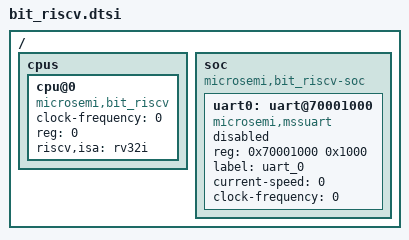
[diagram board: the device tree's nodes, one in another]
/*
 *
 * SPDX-License-Identifier: Apache-2.0
 */

/ {
	#address-cells = <1>;
	#size-cells = <1>;

	cpus {
		#address-cells = <1>;
		#size-cells = <0>;
		cpu@0 {
			clock-frequency = <0>;
			compatible = "microsemi,bit_riscv", "riscv";
			device_type = "cpu";
			reg = <0>;
			riscv,isa = "rv32i";
		};
	};

	soc {
		#address-cells = <1>;
		#size-cells = <1>;
		compatible = "microsemi,bit_riscv-soc", "simple-bus";
		ranges;

		uart0: uart@70001000 {
			compatible = "microsemi,mssuart";
			reg = <0x70001000 0x1000>;
			label = "uart_0";
			status = "disabled";
			current-speed = <0>;
			clock-frequency = <0>;
		};
	};
};
